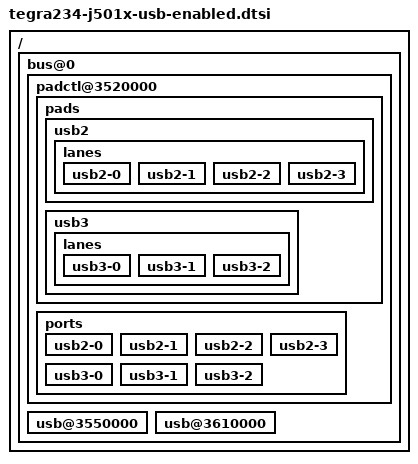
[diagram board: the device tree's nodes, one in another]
// SPDX-License-Identifier: GPL-2.0-only

/ {
	bus@0 {
		padctl@3520000 {
			status = "okay";

			pads {
				usb2 {
					lanes {
						usb2-0 { status = "okay"; };
						usb2-1 { status = "okay"; };
						usb2-2 { status = "okay"; };
						usb2-3 { status = "okay"; };
					};
				};

				usb3 {
					lanes {
						usb3-0 { status = "okay"; };
						usb3-1 { status = "okay"; };
						usb3-2 { status = "okay"; };
					};
				};
			};

			ports {
				usb2-0 { status = "okay"; };
				usb2-1 { status = "okay"; };
				usb2-2 { status = "okay"; };
				usb2-3 { status = "okay"; };
				usb3-0 { status = "okay"; };
				usb3-1 { status = "okay"; };
				usb3-2 { status = "okay"; };
			};
		};

		usb@3550000 {
			status = "okay";
		};

		usb@3610000 {
			status = "okay";
		};
	};
};
